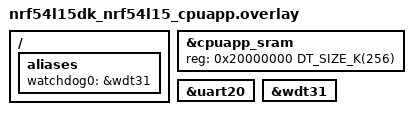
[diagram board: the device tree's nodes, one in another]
/*
 * Copyright (c) 2025 Nordic Semiconductor ASA
 *
 * SPDX-License-Identifier: LicenseRef-Nordic-5-Clause
 */

/ {
	aliases {
		/* Use watchdog wdt31 as the application watchdog */
		watchdog0 = &wdt31;
		/delete-property/ access-decision-indicator;
	};
};

&cpuapp_sram {
	reg = <0x20000000 DT_SIZE_K(256)>;
	ranges = <0x0 0x20000000  0x40000>;
};

/* TODO: re-enable HWFC once it's fixed */
&uart20 {
	/delete-property/ hw-flow-control;
};

&wdt31 {
	status = "okay";
};
